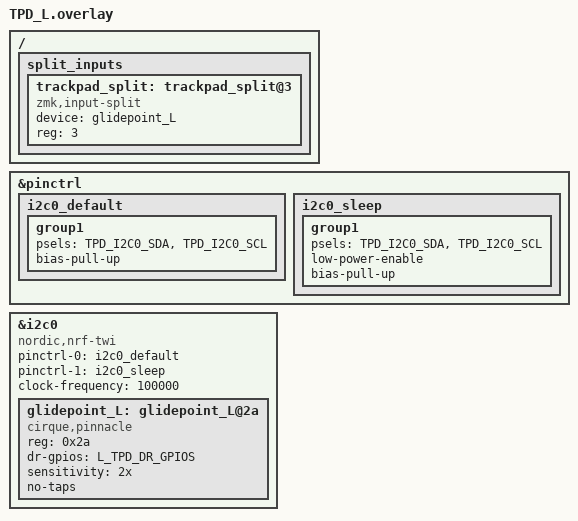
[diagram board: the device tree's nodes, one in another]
#include <dt-bindings/zmk/keys.h>
#include <dt-bindings/zmk/pointing.h>

/ {
    split_inputs {
        #address-cells = <1>;
        #size-cells = <0>;

        trackpad_split: trackpad_split@3 {
            compatible = "zmk,input-split";
            status = "okay";
            device = <&glidepoint_L>;
            reg = <3>;
        };
    };
};

&pinctrl {
    i2c0_default: i2c0_default {
        group1 {
            psels = <TPD_I2C0_SDA>,
                    <TPD_I2C0_SCL>;
            bias-pull-up;
        };
    };

    i2c0_sleep: i2c0_sleep {
        group1 {
            psels = <TPD_I2C0_SDA>,
                    <TPD_I2C0_SCL>;
            low-power-enable;
            bias-pull-up;
        };
    };
};

&i2c0 {
    status = "okay";
    compatible = "nordic,nrf-twi";
    pinctrl-0 = <&i2c0_default>;
    pinctrl-1 = <&i2c0_sleep>;
    pinctrl-names = "default", "sleep";
    clock-frequency = <100000>;

    glidepoint_L: glidepoint_L@2a {
        compatible = "cirque,pinnacle";
        reg = <0x2a>;
        status = "okay";
        dr-gpios = L_TPD_DR_GPIOS;
        sensitivity = "2x";
        no-taps;
    };
};
